# CAL register map
Vendor: Texas Instruments
Peripheral module from a debugger description file (folder am574x).
Registers are 32-bit, access per field, reset 0x0 unless marked. A register's access mark holds for its fields unless they carry their own. Offsets are as the file gives them; lines under a group give offsets from that group; [hi:lo] are bit positions; {n}, {i} and the like mark numbered series; 'fields as' and 'values as' point back to an identical list; <NAME> marks a mode.

## CAL
0x00 CAL_HL_REVISION ro reset not defined — IP Revision Identifier (X.Y.R) Used by software to track features, bugs, and compatibility
  [31:0] REVISION — IP Revision
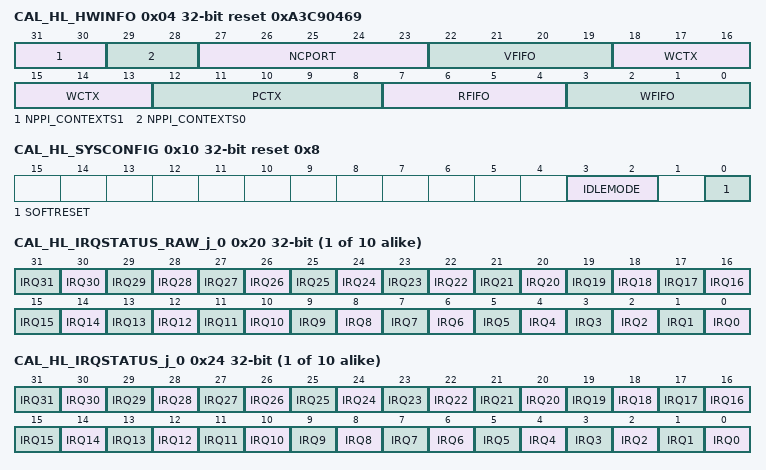
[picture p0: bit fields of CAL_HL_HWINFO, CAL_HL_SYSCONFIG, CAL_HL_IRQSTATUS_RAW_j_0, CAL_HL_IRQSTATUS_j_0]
0x04 CAL_HL_HWINFO ro reset 0xA3C90469 — Information about the IP module's hardware configuration, i.e. typically the module's HDL generics (if any). Actual field format and encoding is up to the module's designer to decide.
  [31:30] NPPI_CONTEXTS1 — Number of contexts for PPI interface #0
    2=EIGHT (PPI interface supported with 8 conetxts); 1=FOUR (PPI interface supported with 4 contexts); 0=ZERO (PPI interface not supported)
  [29:28] NPPI_CONTEXTS0 — Number of contexts for PPI interface #0
    2=EIGHT (PPI interface supported with 8 contexts); 1=FOUR (PPI interface supported with 4 contexts); 0=ZERO (PPI interface not supported)
  [27:23] NCPORT — Number of supported CPORTs (including CPORT #0) minus 1. That number typically corresponds to the number of CPORTs that can provide data from OCPI. E.g. NCPORT=7 means that CAL implements 8 CPorts but one of them (CPORT0) is typically used for data read from memory and typically 7 (CPORT1~CPORT7) can be used for data received on OCPI Note: Equals NCPORT generic parameter minus 1
  [22:19] VFIFO — Video port FIFO size
  [18:13] WCTX — Number of implemented DMA write contexts
  [12:8] PCTX — Number of implemented pixel processing contexts
  [7:4] RFIFO — Read FIFO size 2^RFIFO words of 16 bytes
  [3:0] WFIFO — Write FIFO size 2^WFIFO words of 16 bytes
0x10 CAL_HL_SYSCONFIG reset 0x8 — Clock management configuration
  [3:2] IDLEMODE rw — IDLE protocol configuration
    0=FORCE (Force Idle); 1=NO (No Idle); 3=SMART2 (Smart Idle); 2=SMART1 (Smart Idle)
  [0] SOFTRESET rw — Software reset
    0=NOACTION; 1=RESET (Initiate software reset); 1=PENDING (Reset (software or other) ongoing); 0=DONE (Reset done, no pending action)
0x1C CAL_HL_IRQ_EOI — End Of Interrupt number specification
  [0] LINE_NUMBER rw — Software End Of Interrupt (EOI) control. Write number of interrupt output.
    0=EOI0 (EOI for interrupt output line #0); 0=READ0 (Reads always 0 (no EOI memory))
{0x20+0x10*i} CAL_HL_IRQSTATUS_RAW_j_{i} access not given (i=0..9) — Per-event raw interrupt status vector, line #0. Raw status is set even if event is not enabled.
  [all] fields
    0=NACT (No action); 1=SET (Set event (debug)); 1=PENDING (Event pending); 0=NOEVENT (No event pending)
  [n] IRQ{n} (n=0..31) — Check section CAMSS Interrupt Events for details (access RW W1toSet)
{0x24+0x10*i} CAL_HL_IRQSTATUS_j_{i} access not given (i=0..9) — Per-event 'enabled' interrupt status vector, line #0. Enabled status is not set unless event is enabled.
  [all] fields
    0=NACT (No action); 1=CLEAR (Clear (RAW) event); 1=PENDING (Event pending); 0=NOEVENT (No (enabled) event pending)
  [n] IRQ{n} (n=0..31) — Check section CAMSS Interrupt Events for details (access RW W1toClr)
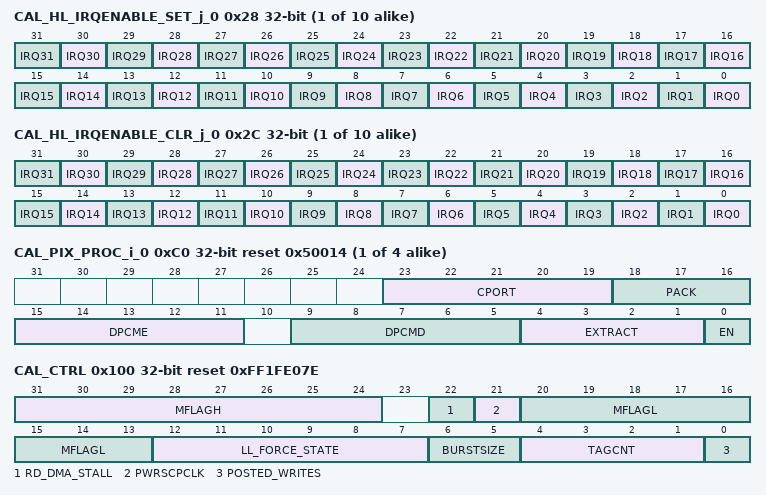
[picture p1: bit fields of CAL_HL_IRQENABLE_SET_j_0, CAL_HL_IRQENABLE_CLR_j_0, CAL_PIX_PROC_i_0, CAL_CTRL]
{0x28+0x10*i} CAL_HL_IRQENABLE_SET_j_{i} access not given (i=0..9) — Per-event interrupt enable bit vector Write 1 to set (enable interrupt). Readout equal to corresponding _CLR register.
  [all] fields
    0=NOACTION; 1=ENABLE (Enable interrupt); 1=ENABLED (Interrupt enabled); 0=DISABLED (Interrupt disabled (masked))
  [n] IRQ{n} (n=0..31) — Check section CAMSS Interrupt Events for details (access RW W1toSet)
{0x2C+0x10*i} CAL_HL_IRQENABLE_CLR_j_{i} access not given (i=0..9) — Per-event interrupt enable bit vector Write 1 to clear (disable interrupt). Readout equal to corresponding _SET register.
  [all] fields
    0=NOACTION; 1=DISABLE (Disable interrupt); 1=ENABLED (Interrupt enabled); 0=DISABLED (Interrupt disabled (masked))
  [n] IRQ{n} (n=0..31) — Check section CAMSS Interrupt Events for details (access RW W1toClr)
{0xC0+4i} CAL_PIX_PROC_i_{i} reset 0x50014 (i=0..3) — Pixel processing control
  [23:19] CPORT rw — CPort ID to process.
  [18:16] PACK rw — Control pixel packing
    6=ARGB (3 samples coded into 3x 8 bits followed by 8-bit padding); 0=B8 (8 bit); 2=B10_MIPI (10 bit - MIPI); 4=B12_MIPI (12 bit - MIPI); 5=B16 (16 bit); 3=B12 (12 bit)
  [15:11] DPCME rw — DPCM encoder
    22=DPCM_16_8_16_1 (16-8-16 Predictor 1); 0=BYPASS; 2=DPCM_10_8_10_1 (10-8-10 Predictor 1); 16=DPCM_14_8_14_1 (14-8-14 Predictor 1); 18=DPCM_16_12_16_1 (16-12-16 Predictor 1); 8=DPCM_12_8_12_1 (12-8-12 Predictor 1); 20=DPCM_16_10_16_1 (16-10-16 Predictor 1); 14=DPCM_14_10_14 (14-10-14 Predictor 1)
  [9:5] DPCMD rw — DPCM Decoder
    22=DPCM_16_8_16_1 (16-8-16 Predictor 1); 6=DPCM_10_6_10_1 (10-6-10 Predictor 1); 10=DPCM_12_7_12_1 (12-7-12 Predictor 1); 7=DPCM_10_6_10_2 (10-6-10 Predictor 2); 0=BYPASS; 2=DPCM_10_8_10_1 (10-8-10 Predictor 1); 8=DPCM_12_8_12_1 (12-8-12 Predictor 1); 16=DPCM_14_8_14_1 (14-8-14 Predictor 1); 18=DPCM_16_12_16_1 (16-12-16 Predictor 1); 5=DPCM_10_7_10_2 (10-7-10 Predictor 2); 12=DPCM_12_6_12_1 (12-6-12 Predictor 1); 4=DPCM_10_7_10_1 (10-7-10 Predictor 1); 20=DPCM_16_10_16_1 (16-10-16 Predictor 1); 14=DPCM_14_10_14 (14-10-14 Predictor 1)
  [4:1] EXTRACT rw — Control pixel extraction from the byte stream
    6=B12_MIPI (12 bit MIPI); 1=B7 (7 bit); 10=B16_LE (16-bit (little endian) = bypass); 7=B14 (14 bit (linear)); 0=B6 (6 bit); 2=B8 (8 bit); 8=B14_MIPI (14 bit MIPI); 9=B16_BE (16-bit (big endian)); 4=B10_MIPI (10 bit MIPI); 5=B12 (12 bit (linear)); 3=B10 (10 bit (linear))
  [0] EN rw — Enable the pixel processing context
    0=DIS (Disabled); 1=EN (Enabled)
0x100 CAL_CTRL reset 0xFF1FE07E — Global control register
  [31:24] MFLAGH rw — Refer to section CAL Write DMA Real Time Traffic.
  [22] RD_DMA_STALL rw — Controls if the pixel stream from the RD DMA's FIFO to the internal pipeline shall be stalled when MFlag/=0. Shall be enabled to protect real time traffic against non real time, memory to memory dataflows through CAL.
    0=DIS (Disabled.); 1=EN (Enabled. The MFlag information is propagated to the RD DMA FIFO readout control.)
  [21] PWRSCPCLK rw — Controls autogating of the PWRSCP clock
    0=AUTO (PWRSCP clock is automatically cut when it is not needed.); 1=FORCE (PWRSCP clock is free running)
  [20:13] MFLAGL rw — Refer to section CAL Write DMA Real Time Traffic
  [12:7] LL_FORCE_STATE wo — Forces the state of the CSI-3 low level protocol state machine. Intended to recover synchronization Writing 0 into this register has no effect. Reads always return 0s bit0: 0: the next OCPI transaction for this CPORT will only contain data 1: the next OCPI transaction for this CPORT will contain the CSI-3 packet header bit1~5: CPort ID (1..31)
  [6:5] BURSTSIZE rw — Maximum allowed burst size for the write DMA.
    0=BURST16 (16 bytes); 1=BURST32 (32 bytes); 3=BURST128 (128 bytes); 2=BURST64 (64 bytes)
  [4:1] TAGCNT rw — Maximum number of outstanding OCP transactions = TAGCNT+1
  [0] POSTED_WRITES rw
    0=NONPOSTED (Generate only non posted writes); 1=POSTED (Generate only posted writes)
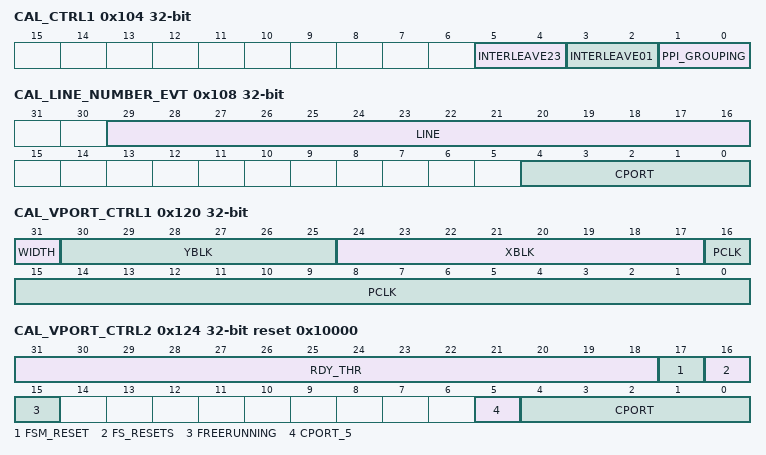
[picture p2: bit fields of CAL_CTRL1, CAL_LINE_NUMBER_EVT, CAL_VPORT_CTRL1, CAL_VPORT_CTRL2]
0x104 CAL_CTRL1 — CAL global control register
  [5:4] INTERLEAVE23 rw — Controls stream interleaving Context #2 and #3
    0=DISABLED; 1=PIX1 (1 pixel from pixel processing context #0 1 pixel from pixel processing context #1 1 pixel from pixel processing context #0 1 pixel from pixel processing context #1 ...); 2=PIX4 (4 pixel from pixel processing context #0 4 pixel from pixel processing context #1 4 pixel from pixel processing context #0 4 pixel from pixel processing context #1 ...)
  [3:2] INTERLEAVE01 rw — Controls stream interleaving Context #0 and #1
    values as INTERLEAVE23
  [1:0] PPI_GROUPING rw — Controls PPI grouping
    0=DISABLED (no PPI grouping); 2=PPI_1 (PPI grouped. Start with PPI_0); 3=PPI_0 (PPI grouped. Start with PPI_1)
0x108 CAL_LINE_NUMBER_EVT — Controls generation of the line number event
  [29:16] LINE rw — 0: Event triggered when PIX_DAT_FS TAG is received by the line number event generator 1~2^14-1: Event triggered when the LINEth occurence of the PIX_DAT_LS TAG is received by the line number event generator.
  [4:0] CPORT rw — CPort ID to monitor
0x120 CAL_VPORT_CTRL1 rw — Video port control register
  [31] WIDTH — Video port width
    0=ONE (1 pixel per PCLK cycle); 1=TWO (2 pixels per PCLK cycle)
  [30:25] YBLK — Vertical blanking = YBLK lines Valid range : 0 ... 63
  [24:17] XBLK — Horizontal blanking = 8*XBLK cycles Valid range = 0..2040 cycles
  [16:0] PCLK — Video port pixel clock = FCLK * PCLK / 2^16 Valid range: 0 .. 2^16
0x124 CAL_VPORT_CTRL2 reset 0x10000 — Video port control register
  [31:18] RDY_THR rw — Data shall be send to the video port after frame start only when (RDY_THR+1)*4 pixels are ready and the 4 PCLK cycles (require before each frame start) have been sent. This register only controls when the 1st pixels of each frame are sent. Consecutive pixels shall be sent immediately. The threshold shall be less or equal to the FIFO size.
  [17] FSM_RESET wo — Forces a reset of the video port FSM
    0=NOEFFECT; 1=RESET
  [16] FS_RESETS rw — Controls the behavior of the timing generator when a data tagged as PIX_DAT_FS is received.
    0=NO (Data is processed normally); 1=YES (The state machine is reset on every FS)
  [15] FREERUNNING rw — Controls PCLK generation during IDLE.
    0=GATED (Clock gated during idle (recommended setting)); 1=FREE (Free running)
  [5] CPORT_5 rw — 0x0: Disable Video Ports 2, 3, and 4. Video Port 1 stays enabled.
    1=Enable Video Ports 2, 3, and 4. Video Port 1 is already enabled.
  [4:0] CPORT rw — Cport ID Valid range=0..(CAL_HL_HWINFO.NCPORT-1)
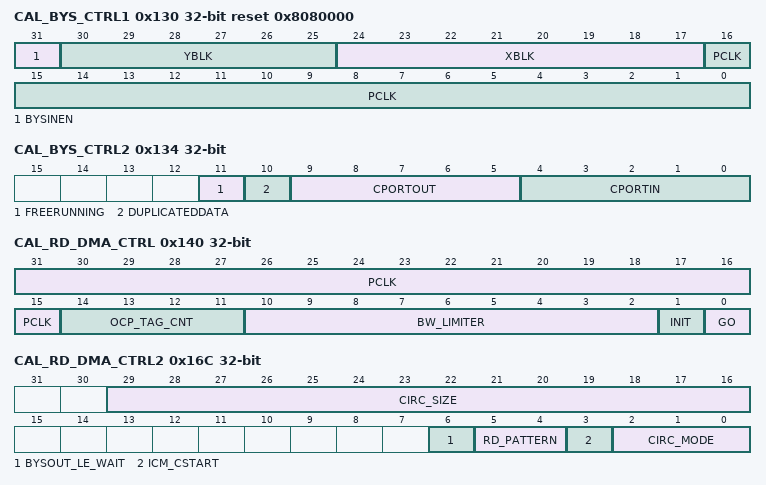
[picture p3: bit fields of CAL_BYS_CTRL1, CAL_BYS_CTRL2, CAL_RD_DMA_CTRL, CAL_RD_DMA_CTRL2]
0x130 CAL_BYS_CTRL1 rw reset 0x8080000 — BYS port control register
  [31] BYSINEN — Enable/disable the BYS input port Note: the BYS output port is disabled by setting PCLK=0
    0=DIS (Disable. Ignore data received on the BYS input port.); 1=EN (Enable. Process data received on the BYSin port)
  [30:25] YBLK — Vertical blanking = YBLK lines Valid range : 0 ... 63
  [24:17] XBLK — Horizontal blanking = 8*XBLK cycles Valid range = 0..2040 cycles
  [16:0] PCLK — BYSout port pixel clock = FCLK * PCLK / 2^16 Valid range: 0 .. 2^16 0 disables the BYS output port
0x134 CAL_BYS_CTRL2 — BYS port control register
  [11] FREERUNNING rw — Controls PCLK generation when the BYSout state machine is in the IDLE state
    0=NO (No. PCLK gated during IDLE); 1=YES (Yes. PCLK running at the speed defined by .PCLK during IDLE.)
  [10] DUPLICATEDDATA rw — Control if data sent to the BYS output port should also be send to the DPCM encoder
    0=NO; 1=YES
  [9:5] CPORTOUT rw — BYS output port processes data received with the CPORT ID defined in this register
  [4:0] CPORTIN rw — Cport ID used for data received from the BYSin port
0x140 CAL_RD_DMA_CTRL rw — Read DMA control register
  [31:15] PCLK — Controls the data rate at which data is read from the read DMA FIFO and sent to the internal processing pipeline. Data rate = FCLK * 8 * PCLK / 2^16 Bytes/s HW guarantees that data is never sent at faster rate than defined by this register. The data may be sent at slower rate when the RD DMA FIFO is empty or the processing pipeline is busy (data from OCPI has higher priority) Missed slots are not cummulated. Valid range: 0 .. 2^16
  [14:11] OCP_TAG_CNT — Maximum allowed number of outstanding OCP read requests minus 1 (i.e. 0xF meand up to 16 outstanding requests)
  [10:2] BW_LIMITER — Defines a minimum cycle count between to consecutive read requests issued by the RD DMA. Used to limit the SDRAM load in memory to memory mode. The pixel rate should be controlled at video port level when data read from memory is send to the video port. Valid range = 9..4095 cycles
  [1] INIT — Enable reading of DPCM decoder initialization data from SDRAM
    0=DIS (Disabled); 1=EN (Enabled)
  [0] GO — Start data read from memory. This bit is set by SW and automatically cleared by HW when the frame has been processed.
    0=DIS (No effect); 1=EN (Start read DMA); 1=BUSY (Read DMA BUSY / it is currently fetching data from memory and sends it to the processing pipeline); 0=IDLE (Read DMA idle / ready to receive the next start trigger from SW)
0x144 CAL_RD_DMA_PIX_ADDR — Byte address of the top left corner of the buffer to read in system memory. Used for Y when YUV420 mode is selected Shall be 16 byte aligned for YUV420
  [31:3] ADDR rw — Address, in words of 8 bytes.
0x148 CAL_RD_DMA_PIX_OFST — Byte offset between two consecutive line starts Shall be 16 byte aligned for YUV420
  [31:4] OFST rw — Offset in words of 16 bytes. This value should be a multiple of 128 bytes for best performance.
0x14C CAL_RD_DMA_XSIZE — Number of bytes to read per line.
  [31:19] XSIZE rw — Words of 64-bits to read per line. Valid range = 2..8191
0x150 CAL_RD_DMA_YSIZE — Number of lines to read. Valid range 1 ~ 16383
  [29:16] YSIZE rw
0x154 CAL_RD_DMA_INIT_ADDR — Read address. Used for DPCM initialization (.INIT=1) or UV data .RD_PATTERN=YUV420 Shall be 16 byte aligned for YUV420
  [31:3] ADDR rw — Address, in words of 8 bytes.
0x168 CAL_RD_DMA_INIT_OFST — Byte offset between two consecutive line starts. Used for DPCM initialization (.INIT=1) or UV data .RD_PATTERN=YUV420 Shall be 16 byte aligned for YUV420
  [31:3] OFST rw — Offset in words of 8 bytes.
0x16C CAL_RD_DMA_CTRL2 — Read DMA control register
  [29:16] CIRC_SIZE rw — Circular buffer size minus one. Granularity defined by CIRC_MODE. E.g. 1M lines for CIRC_MODE=4 &amp;&amp; CIRC_SIZE=0x3FFF
  [6] BYSOUT_LE_WAIT rw — Controls the behavior of the RD DMA when the line end is reached.
    0=FREERUNNING (RD DMA starts the next line when the current line finishes without waiting for other events.); 1=WAITFORBYSOUT (RD DMA is stalled at each line end until BYSout finishes generating horizontal blanking (i.e. the state machine is in the IDLE state). This prevents back pressuring the shared pipelined during horizontal blanking generation. This bit should be set when .XBLK > 0 and real time traffic goes through the shared pipeline.)
  [5:4] RD_PATTERN rw — Data read pattern
    0=LINEAR; 1=YUV420; 3=RD2SKIP4 (Read 2 lines Skip 4 lines); 2=RD2SKIP2 (Read two lines Skip two lines)
  [3] ICM_CSTART rw — Enables monitoring of the ICM_CSTART signal
    0=DIS (Disabled. Ignore CSTART input); 1=EN (Enabled. Read the number of lines defined by CIRC_SIZE and CIRC_CTRL for each received CSTART pulse.)
  [2:0] CIRC_MODE rw — Circular mode control
    1=ONE (Granularity = 1 line); 0=DIS (Circular mode disabled); 2=FOUR (Granularity = 4 lines); 4=SIXTYFOUR (Granularity = 64 lines); 3=SIXTEEN (Granularity = 16 lines)
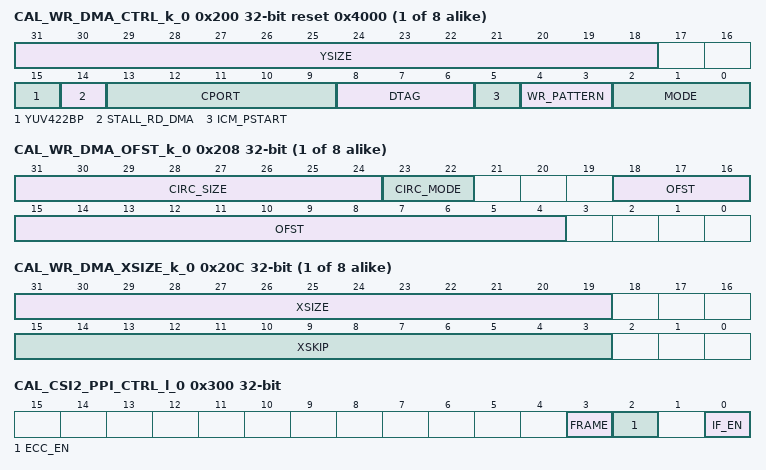
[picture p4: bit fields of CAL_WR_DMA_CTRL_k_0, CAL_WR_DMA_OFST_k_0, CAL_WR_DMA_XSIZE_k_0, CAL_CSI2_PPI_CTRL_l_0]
{0x200+0x10*i} CAL_WR_DMA_CTRL_k_{i} reset 0x4000 (i=0..7) — Write DMA control register
  [31:18] YSIZE rw — Maximum number of lines the WR DMA can write to memory. That feature is typically used to prevent writes outside of an allocated memory buffer (may, for example, happen when sync information is lost). 0: No limitation. All received lines are written to memory. 1~2^14-1: maximum number of lines to write to memory
  [15] YUV422BP rw — Activates YUV422BP conversion from YUV422. Requires two consecutive WrDMA channels where first channel is even and second is odd. Both channels shall be programmed identically except for DMA destination address.
    0=YUV422BP_conversion_disabled; 1=YUV422BP_conversion_enabled
  [14] STALL_RD_DMA rw — Controls if a the RD DMA shall be stalled when the write context is stalled because it waits for the PSTART pulse.
    0=DISABLED (Don't stall the read DMA); 1=ENABLE (Stall the read DMA if the write DMA context is stalled.)
  [13:9] CPORT rw — Cport ID
  [8:6] DTAG rw — Store data tagged as DTAG
    6=D6 (reserved); 1=ATT_DAT (Attribute data TAG=ATT_DAT_S; ATT_DAT; ATT_DAT_E); 7=D7 (reserved); 0=ATT_HDR (Attribute packet headers. TAG=ATT_HDR_S, ATT_HDR_E); 2=CTRL (Control packets TAG=CTRL_HDR_S; CTRL_HDR_E); 4=PIX_DAT (Pixel data TAG=PIX_DAT_FS; PIX_DAT_LS; PIX_DAT; PIX_DAT_LE; PIX_DAT_FE; FE_CODE); 5=D5 (reserved); 3=PIX_HDR (Pixel packet headers TAG=PIX_HDR_S; PIX_HDR_E)
  [5] ICM_PSTART rw — Enables monitoring of the ICM_PSTART[x] signal
    0=DIS (Disabled. Ignore PSTART input); 1=EN (Enabled. Write the number of lines defined by .CIRC_MODE for each received PSTART pulse.)
  [4:3] WR_PATTERN rw — Data write pattern. The write pattern must be set to linear for formats that don't have a concept of lines.
    0=LINEAR; 3=WR2SKIP4 (Write 2 lines Skip 4 lines); 2=WR2SKIP2 (Write two lines Skip two lines)
  [2:0] MODE rw
    1=SHD (Ping/pong destination address on every frame); 0=DIS (Disable); 2=CNT (Continously write data to memory); 4=CONST (Use as base address.); 3=CNT_INIT (Initialize start address for continous mode. The 1st frame will be written at this address and consecutive frames will be appended.)
{0x204+0x10*i} CAL_WR_DMA_ADDR_k_{i} (i=0..7) — Byte address of the top left corner of the buffer to write in system memory
  [31:4] ADDR rw — Destination address, in words of 16 bytes. This value should be a multiple of 128 bytes for best performance.
{0x208+0x10*i} CAL_WR_DMA_OFST_k_{i} (i=0..7) — Offset between two consecutive line starts. Signed value. SW can directly write a signed 32-bit offset into that register. Valid range = -262144 .. 262143
  [31:24] CIRC_SIZE rw — Circular buffer size minus one. Unit defined by the CIRC_MODE register. E.g. Circular buffer size = 16k lines when CIRC_SIZE=255 and CIRC_MODE=3
  [23:22] CIRC_MODE rw — Defines the granularity for circular buffer mode. Circular adressing mode shall be disabled (CIRC_MODE=0) when - CAL_WR_DMA_CTRL_k.MODE is not CONST - for formats that don't have a concept of lines
    0=DISABLED (Circular addressing mode disabled); 1=ONE (1 Line); 3=SIXTYFOUR (64 lines); 2=FOUR (4 lines)
  [18:4] OFST rw — S14. Offset in words of 16 bytes.
{0x20C+0x10*i} CAL_WR_DMA_XSIZE_k_{i} (i=0..7) — Defines the size of a line written to memory. The minimum size to be written must be >= 16 bytes
  [31:19] XSIZE rw — Words of 64-bits to write per line Valid range = 0 or 1..n 0 : write the complete stream until the end is detected. n = stream size in words of 64 bits
  [15:3] XSKIP rw — Words of 64 bits to skip from the line start. Valid range: 0...n-1 n = number or 64-bit words in the stream
0x300 CAL_CSI2_PPI_CTRL_l_0 — Controls the low level CSI-2 protocol interface (PPI)
  [3] FRAME rw — Set the modality in which IF_EN works.
    0=IMMEDIATE (If IF_EN = 0 the interface is disabled immediately.); 1=FRAME (If IF_EN = 1 the interface is disabled after all FEC sync code have been received for the active contexts.)
  [2] ECC_EN rw — Enables the Error Correction Code check for the received header (short and long packets for all virtual channel ids).
    0=DISABLE (Disabled); 1=ENABLE (Enabled)
  [0] IF_EN rw — Enables the physical interface to the module.
    0=DISABLE (The interface is disabled. If .FRAME = 0, it is disabled immediately. If .FRAME = 1, it is disabled when all active contexts have received the FE sync code.); 1=ENABLE (The interface is enabled immediately, the data acquisition starts on the next FS sync code.)
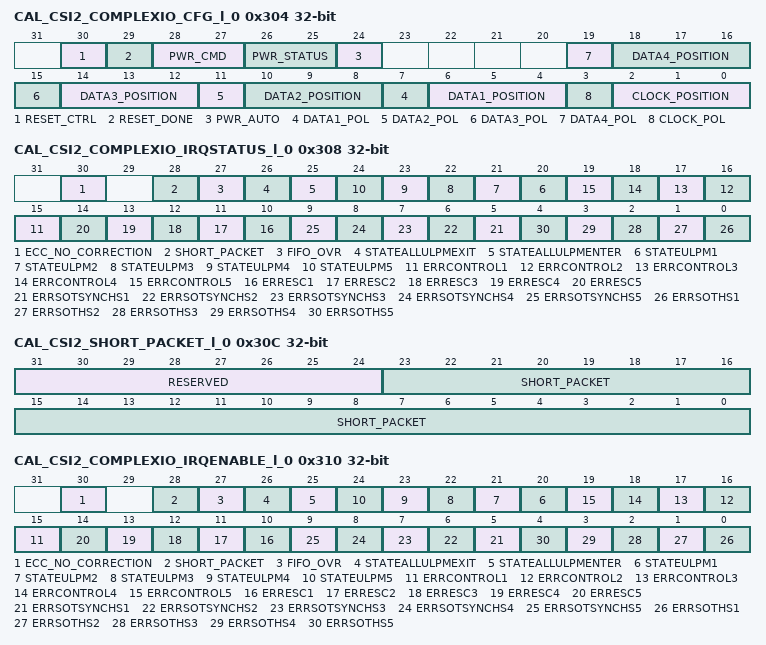
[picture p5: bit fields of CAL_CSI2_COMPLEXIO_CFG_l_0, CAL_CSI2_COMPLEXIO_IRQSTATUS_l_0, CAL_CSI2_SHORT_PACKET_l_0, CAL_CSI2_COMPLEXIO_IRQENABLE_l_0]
0x304 CAL_CSI2_COMPLEXIO_CFG_l_0 — COMPLEXIO CONFIGURATION REGISTER This register contains the lane configuration for the order and position of the lanes (clock and data) and the polarity order for the control of the PHY differential signals in addition to the control bit for the power FSM.
  [30] RESET_CTRL rw — Controls the reset of the complex IO
    0=RESET (Complex IO reset active.); 1=OPERATIONAL (Complex IO reset de-asserted.)
  [29] RESET_DONE ro — Internal reset monitoring of the power domain using the PPI byte clock from the complex io
    1=RESETCOMPLETED; 0=RESETONGOING (Internal module reset is on going.)
  [28:27] PWR_CMD rw — Command for power control of the complex io
    0=STATE_OFF (Command to change to OFF state); 1=STATE_ON (Command to change to ON state); 2=STATE_ULP (Command to change to Ultra Low Power state)
  [26:25] PWR_STATUS ro — Status of the power control of the complex io
    2=STATE_ULP (Complex IO in Ultra Low Power state); 1=STATE_ON (Complex IO in ON state); 0=STATE_OFF (Complex IO in OFF state)
  [24] PWR_AUTO rw — Automatic switch between ULP and ON states based on ULPM signals from complex iO
    0=DISABLE; 1=ENABLE
  [4n+3] DATA{n}_POL rw (n=1..4) — +/- differential pin order of DATA lane {n}.
    0=PLUSMINUS (+/- pin order); 1=MINUSPLUS (-/+ pin order)
  [18:16] DATA4_POSITION rw — Position and order of the DATA lane 4. The values 6 and 7 are reserved.
    {v}=POSITION_{v} (Data lane 4 is at the position {v}.) (v=1..5); 0=NOT_USED (Not used/connected)
  [14:12] DATA3_POSITION rw — Position and order of the DATA lane 3. The values 6 and 7 are reserved.
    {v}=POSITION_{v} (Data lane 3 is at the position {v}.) (v=1..5); 0=NOT_USED (Not used/connected)
  [10:8] DATA2_POSITION rw — Position and order of the DATA lane 2. The values 6 and 7 are reserved.
    {v}=POSITION_{v} (Data lane 2 is at the position {v}.) (v=1..5); 0=NOT_USED (Not used/connected)
  [6:4] DATA1_POSITION rw — Position and order of the DATA lane 1. 0, 6 and 7 are reserved. The data lane 1 is always present.
    {v}=POSITION_{v} (Data lane 1 is at the position {v}.) (v=1..5)
  [3] CLOCK_POL rw — +/- differential pin order of CLOCK lane.
    0=PLUSMINUS (+/- pin order); 1=MINUSPLUS (-/+ pin order)
  [2:0] CLOCK_POSITION rw — Position and order of the CLOCK lane. 0, 6 and 7 are reserved. The clock lane is always present.
    {v}=POSITION_{v} (Clock lane is at the position {v}.) (v=1..5)
0x308 CAL_CSI2_COMPLEXIO_IRQSTATUS_l_0 access not given — INTERRUPT STATUS REGISTER - All errors from complex IO #1
  [all] fields
    0=FALSE (READS: Event is false. WRITES: Status bit unchanged.); 1=TRUE (READS: Event is true (pending). WRITES: Status bit is reset.)
  [30] ECC_NO_CORRECTION — ECC has not been used to correct the header because there is more than 1-bit error (short and long packets). (access RW W1toClr)
  [28] SHORT_PACKET — Short packet (other than FS, FE, LS, LE) received. (access RW W1toClr)
  [27] FIFO_OVR — CSI-2 low level protocol interface FIFO overflow (access RW W1toClr)
  [26] STATEALLULPMEXIT — At least one of the active lanes has exit the ULPM (access RW W1toClr)
  [25] STATEALLULPMENTER — All active lanes are entering in ULPM. (access RW W1toClr)
  [n+19] STATEULPM{n} (n=1..5) — Lane #{n} in Ultra Low Power Mode (access RW W1toClr)
  [n+14] ERRCONTROL{n} (n=1..5) — Control error for lane #{n} (access RW W1toClr)
  [n+9] ERRESC{n} (n=1..5) — Escape entry error for lane #{n} (access RW W1toClr)
  [n+4] ERRSOTSYNCHS{n} (n=1..5) — Start of transmission sync error for lane #{n} (access RW W1toClr)
  [n-1] ERRSOTHS{n} (n=1..5) — Start of transmission error for lane #{n} (access RW W1toClr)
0x30C CAL_CSI2_SHORT_PACKET_l_0 ro — SHORT PACKET INFORMATION - This register sets the 24-bit DATA_ID + Short Packet Data Field when the data type is between 0x8 and x0F
  [31:24] RESERVED — Reads returns 0.
  [23:0] SHORT_PACKET — Short Packet information: DATA ID + DATA FIELD
0x310 CAL_CSI2_COMPLEXIO_IRQENABLE_l_0 — INTERRUPT ENABLE REGISTER - All errors from complex IO #1
  [all] fields
    0=DISABLE (Event is masked); 1=ENABLE (Event generates an interrupt when it occurs)
  [30] ECC_NO_CORRECTION rw — ECC has not been used to correct the header because there is more than 1-bit error (short and long packets).
  [28] SHORT_PACKET rw — Short packet (other than FS, FE, LS, LE) received.
  [27] FIFO_OVR rw — CSI-2 low level protocol interface FIFO overflow
  [26] STATEALLULPMEXIT rw — At least one of the active lanes has exit the ULPM
  [25] STATEALLULPMENTER rw — All active lanes are entering in ULPM.
  [n+19] STATEULPM{n} rw (n=1..5) — Lane #{n} in Ultra Low Power Mode
  [n+14] ERRCONTROL{n} rw (n=1..5) — Control error for lane #{n}
  [n+9] ERRESC{n} rw (n=1..5) — Escape entry error for lane #{n}
  [n+4] ERRSOTSYNCHS{n} rw (n=1..5) — Start of transmission sync error for lane #{n}
  [n-1] ERRSOTHS{n} rw (n=1..5) — Start of transmission error for lane #{n}
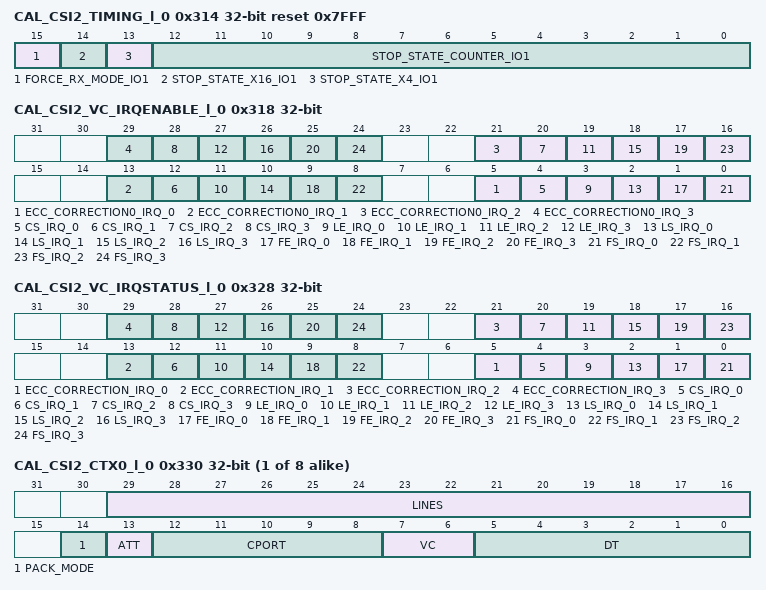
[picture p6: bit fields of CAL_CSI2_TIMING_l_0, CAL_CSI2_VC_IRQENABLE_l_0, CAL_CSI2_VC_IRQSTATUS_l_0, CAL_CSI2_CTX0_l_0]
0x314 CAL_CSI2_TIMING_l_0 reset 0x7FFF — TIMING REGISTER This register shall not be =modified when .IF_EN=1 It is used to indicate the number of functional clock cycles for the Stop State monitoring.
  [15] FORCE_RX_MODE_IO1 rw — Control of ForceRxMode signal
    0=DEASSERTION (De-assertion of ForceRxMode. The HW reset the bit at the end of the Force RX Mode assertion. The SW can reset the bit in order to stop the assertion of the ForceRXMode signal prior to the completion of the period.); 1=ASSERTION (Assertion of ForceRxMode)
  [14] STOP_STATE_X16_IO1 rw — Multiplication factor for the number of L3 cycles defined in STOP_STATE_COUNTER bit-field
    0=DISABLE (The number of L3 cycles defined in STOP_STATE _COUNTER is multiplied by 1x); 1=ENABLE (The number of L3 cycles defined in STOP_STATE _COUNTER is multiplied by 16x)
  [13] STOP_STATE_X4_IO1 rw — Multiplication factor for the number of L3 cycles defined in STOP_STATE_COUNTER bit-field
    0=DISABLE (The number of L3 cycles defined in STOP_STATE _COUNTER is multiplied by 1x); 1=ENABLE (The number of L3 cycles defined in STOP_STATE _COUNTER is multiplied by 4x)
  [12:0] STOP_STATE_COUNTER_IO1 rw — Stop State counter for monitoring. It indicates the number of L3 to monitor for Stop State before de-asserting ForceRxMode (Complex IO #1). The value is from 0 to 8191.
0x318 CAL_CSI2_VC_IRQENABLE_l_0 — INTERRUPT ENABLE REGISTER - Virtual channels
  [all] fields
    values as the fields of CAL_CSI2_COMPLEXIO_IRQENABLE_l_0
  [8n+5] ECC_CORRECTION0_IRQ_{n} rw (n=0..3) — ECC has been used to correct the only 1-bit error
  [8n+4] CS_IRQ_{n} rw (n=0..3) — Check-Sum of the payload mismatch detection
  [8n+3] LE_IRQ_{n} rw (n=0..3) — Line end sync code detection.
  [8n+2] LS_IRQ_{n} rw (n=0..3) — Line start sync code detection.
  [8n+1] FE_IRQ_{n} rw (n=0..3) — Frame end sync code detection.
  [8n] FS_IRQ_{n} rw (n=0..3) — Frame start sync code detection.
0x328 CAL_CSI2_VC_IRQSTATUS_l_0 access not given — INTERRUPT STATUS REGISTER - Virtual channels This register regroups all the events related to Context.
  [all] fields
    values as the fields of CAL_CSI2_COMPLEXIO_IRQSTATUS_l_0
  [8n+5] ECC_CORRECTION_IRQ_{n} (n=0..3) — ECC has been used to do the correction of the only 1-bit error status (access RW W1toClr)
  [8n+4] CS_IRQ_{n} (n=0..3) — Check-Sum mismatch status. (access RW W1toClr)
  [8n+3] LE_IRQ_{n} (n=0..3) — Line end sync code detection status. (access RW W1toClr)
  [8n+2] LS_IRQ_{n} (n=0..3) — Line start sync code detection status. (access RW W1toClr)
  [8n+1] FE_IRQ_{n} (n=0..3) — Frame end sync code detection status. (access RW W1toClr)
  [8n] FS_IRQ_{n} (n=0..3) — Frame start sync code detection status. (access RW W1toClr)
{0x330+4i} CAL_CSI2_CTX{i}_l_0 (i=0..7) — Context control
  [29:16] LINES rw — Number of expected lines 0: Number of lines unknown. TAG generation FSM will insert a dummy line upon reception of a FE short packet. Other values: Number of lines
  [14] PACK_MODE rw — Controls the data packing behavior
    0=LINE (Line mode Data is packed in between line boundaries. Line boundaries are preserved. Recomended mode for pixel data.); 1=FRAME (Frame mode Data is packed in between frame boundaries. Line boundaries are removed. Recommended mode for JPEG data.)
  [13] ATT rw — Selects which tags to use for the CAL internal pipeline
    0=PIX (Data tagged as Pixel Data); 1=ATT (Data tagged as Attributes / Embedded Data)
  [12:8] CPORT rw — CAL internal CPort ID to use for Data
  [7:6] VC rw — Virtual channel
  [5:0] DT rw — DT value received over CSI-2 to use for data. 0x00 : context is disabled (don't receive data) 0x01 : filter is disabled (accept any DT) 0x02 ~ 0x0F: reserved 0x10 ~ 0x3F: receive data with Data Type field = DT
{0x350+4i} CAL_CSI2_STATUS{i}_l_0 ro (i=0..7) — Context status register
  [15:0] FRAME — Frame number. Matches the frame number sent by the camera when the camera transmits it. Otherwise, incremented by one on every FS short packet for this context. Reset when the context is enabled.
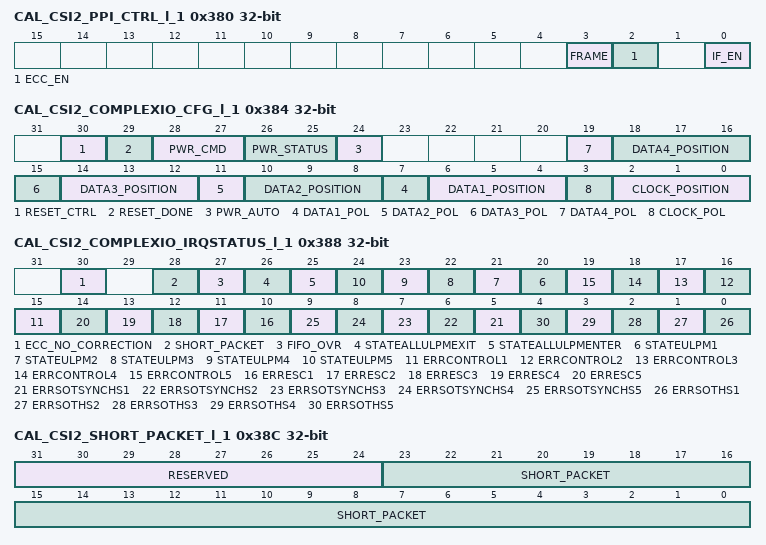
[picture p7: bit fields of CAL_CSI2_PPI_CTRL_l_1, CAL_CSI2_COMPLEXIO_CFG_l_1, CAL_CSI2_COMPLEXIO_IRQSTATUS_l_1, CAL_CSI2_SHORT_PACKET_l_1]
0x380 CAL_CSI2_PPI_CTRL_l_1 — Controls the low level CSI-2 protocol interface (PPI)
  fields as CAL_CSI2_PPI_CTRL_l_0
0x384 CAL_CSI2_COMPLEXIO_CFG_l_1 — COMPLEXIO CONFIGURATION REGISTER This register contains the lane configuration for the order and position of the lanes (clock and data) and the polarity order for the control of the PHY differential signals in addition to the control bit for the power FSM.
  fields as CAL_CSI2_COMPLEXIO_CFG_l_0
0x388 CAL_CSI2_COMPLEXIO_IRQSTATUS_l_1 access not given — INTERRUPT STATUS REGISTER - All errors from complex IO #1
  fields as CAL_CSI2_COMPLEXIO_IRQSTATUS_l_0
0x38C CAL_CSI2_SHORT_PACKET_l_1 ro — SHORT PACKET INFORMATION - This register sets the 24-bit DATA_ID + Short Packet Data Field when the data type is between 0x8 and x0F
  fields as CAL_CSI2_SHORT_PACKET_l_0
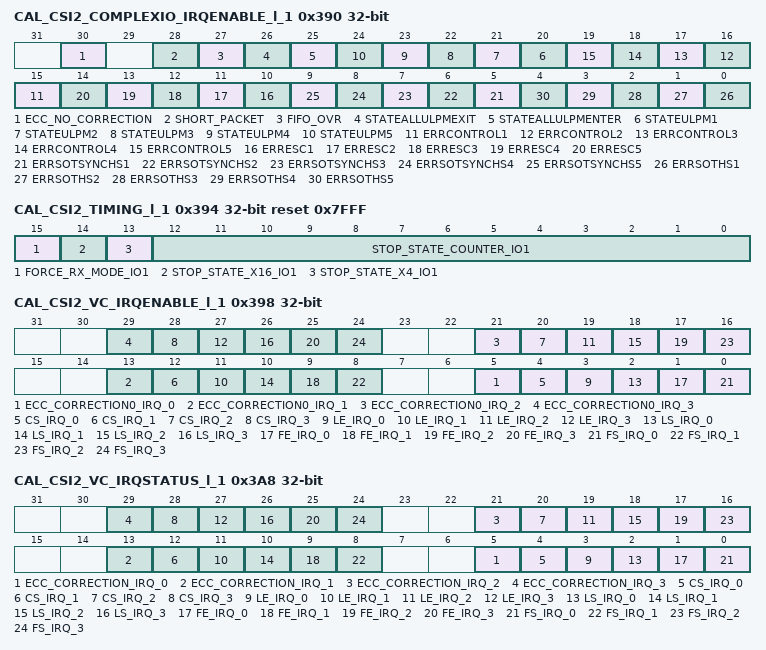
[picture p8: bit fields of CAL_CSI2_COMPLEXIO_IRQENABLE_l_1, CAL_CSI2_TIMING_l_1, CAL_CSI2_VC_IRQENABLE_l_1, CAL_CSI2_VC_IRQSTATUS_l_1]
0x390 CAL_CSI2_COMPLEXIO_IRQENABLE_l_1 — INTERRUPT ENABLE REGISTER - All errors from complex IO #1
  fields as CAL_CSI2_COMPLEXIO_IRQENABLE_l_0
0x394 CAL_CSI2_TIMING_l_1 reset 0x7FFF — TIMING REGISTER This register shall not be =modified when .IF_EN=1 It is used to indicate the number of functional clock cycles for the Stop State monitoring.
  fields as CAL_CSI2_TIMING_l_0
0x398 CAL_CSI2_VC_IRQENABLE_l_1 — INTERRUPT ENABLE REGISTER - Virtual channels
  fields as CAL_CSI2_VC_IRQENABLE_l_0
0x3A8 CAL_CSI2_VC_IRQSTATUS_l_1 access not given — INTERRUPT STATUS REGISTER - Virtual channels This register regroups all the events related to Context.
  fields as CAL_CSI2_VC_IRQSTATUS_l_0
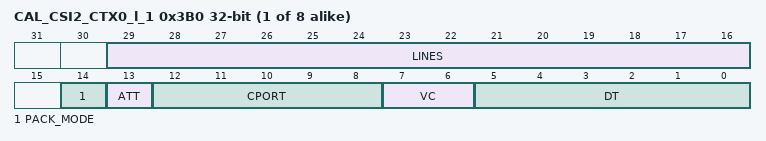
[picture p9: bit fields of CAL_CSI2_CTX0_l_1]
{0x3B0+4i} CAL_CSI2_CTX{i}_l_1 (i=0..7) — Context control
  fields as CAL_CSI2_CTX0_l_0
{0x3D0+4i} CAL_CSI2_STATUS{i}_l_1 ro (i=0..7) — Context status register
  fields as CAL_CSI2_STATUS0_l_0
